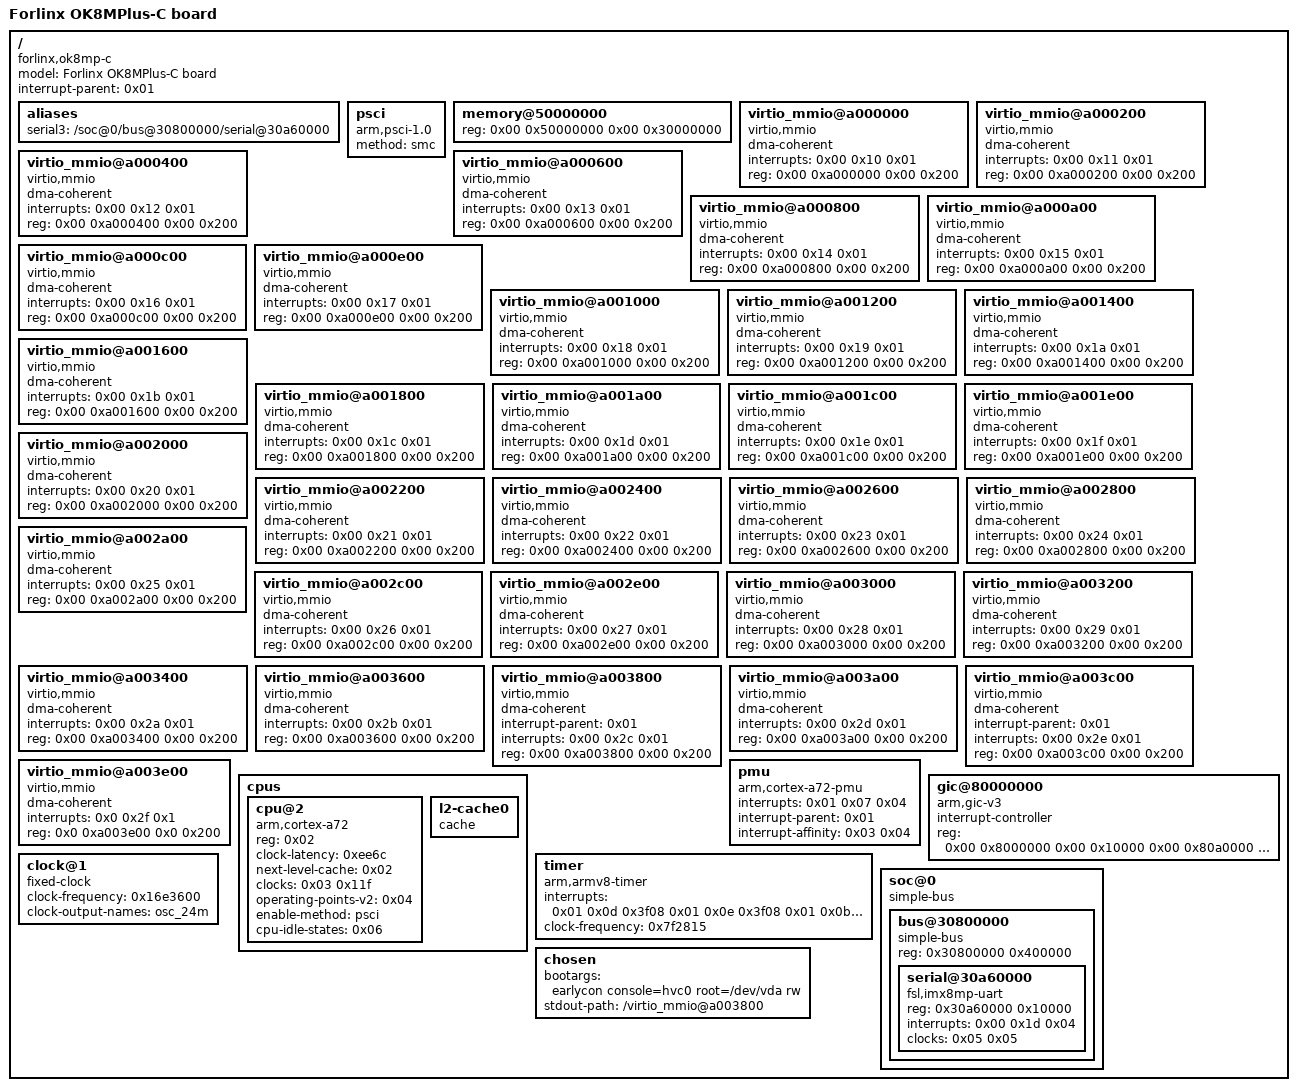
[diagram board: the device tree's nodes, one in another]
/dts-v1/;

/ {
	compatible = "forlinx,ok8mp-c\0fsl,imx8mp-evk\0fsl,imx8mp";
	model = "Forlinx OK8MPlus-C board";
	interrupt-parent = <0x01>;
	#address-cells = <0x02>;
	#size-cells = <0x02>;

	aliases {
		serial3 = "/soc@0/bus@30800000/serial@30a60000";
	};

	psci {
		compatible = "arm,psci-1.0";
		method = "smc";
	};

	memory@50000000 {
		device_type = "memory";
		reg = <0x00 0x50000000 0x00 0x30000000>;
	};

	virtio_mmio@a000000 {
		dma-coherent;
		interrupts = <0x00 0x10 0x01>;
		reg = <0x00 0xa000000 0x00 0x200>;
		compatible = "virtio,mmio";
	};

	virtio_mmio@a000200 {
		dma-coherent;
		interrupts = <0x00 0x11 0x01>;
		reg = <0x00 0xa000200 0x00 0x200>;
		compatible = "virtio,mmio";
	};

	virtio_mmio@a000400 {
		dma-coherent;
		interrupts = <0x00 0x12 0x01>;
		reg = <0x00 0xa000400 0x00 0x200>;
		compatible = "virtio,mmio";
	};

	virtio_mmio@a000600 {
		dma-coherent;
		interrupts = <0x00 0x13 0x01>;
		reg = <0x00 0xa000600 0x00 0x200>;
		compatible = "virtio,mmio";
	};

	virtio_mmio@a000800 {
		dma-coherent;
		interrupts = <0x00 0x14 0x01>;
		reg = <0x00 0xa000800 0x00 0x200>;
		compatible = "virtio,mmio";
	};

	virtio_mmio@a000a00 {
		dma-coherent;
		interrupts = <0x00 0x15 0x01>;
		reg = <0x00 0xa000a00 0x00 0x200>;
		compatible = "virtio,mmio";
	};

	virtio_mmio@a000c00 {
		dma-coherent;
		interrupts = <0x00 0x16 0x01>;
		reg = <0x00 0xa000c00 0x00 0x200>;
		compatible = "virtio,mmio";
	};

	virtio_mmio@a000e00 {
		dma-coherent;
		interrupts = <0x00 0x17 0x01>;
		reg = <0x00 0xa000e00 0x00 0x200>;
		compatible = "virtio,mmio";
	};

	virtio_mmio@a001000 {
		dma-coherent;
		interrupts = <0x00 0x18 0x01>;
		reg = <0x00 0xa001000 0x00 0x200>;
		compatible = "virtio,mmio";
	};

	virtio_mmio@a001200 {
		dma-coherent;
		interrupts = <0x00 0x19 0x01>;
		reg = <0x00 0xa001200 0x00 0x200>;
		compatible = "virtio,mmio";
	};

	virtio_mmio@a001400 {
		dma-coherent;
		interrupts = <0x00 0x1a 0x01>;
		reg = <0x00 0xa001400 0x00 0x200>;
		compatible = "virtio,mmio";
	};

	virtio_mmio@a001600 {
		dma-coherent;
		interrupts = <0x00 0x1b 0x01>;
		reg = <0x00 0xa001600 0x00 0x200>;
		compatible = "virtio,mmio";
	};

	virtio_mmio@a001800 {
		dma-coherent;
		interrupts = <0x00 0x1c 0x01>;
		reg = <0x00 0xa001800 0x00 0x200>;
		compatible = "virtio,mmio";
	};

	virtio_mmio@a001a00 {
		dma-coherent;
		interrupts = <0x00 0x1d 0x01>;
		reg = <0x00 0xa001a00 0x00 0x200>;
		compatible = "virtio,mmio";
	};

	virtio_mmio@a001c00 {
		dma-coherent;
		interrupts = <0x00 0x1e 0x01>;
		reg = <0x00 0xa001c00 0x00 0x200>;
		compatible = "virtio,mmio";
	};

	virtio_mmio@a001e00 {
		dma-coherent;
		interrupts = <0x00 0x1f 0x01>;
		reg = <0x00 0xa001e00 0x00 0x200>;
		compatible = "virtio,mmio";
	};

	virtio_mmio@a002000 {
		dma-coherent;
		interrupts = <0x00 0x20 0x01>;
		reg = <0x00 0xa002000 0x00 0x200>;
		compatible = "virtio,mmio";
	};

	virtio_mmio@a002200 {
		dma-coherent;
		interrupts = <0x00 0x21 0x01>;
		reg = <0x00 0xa002200 0x00 0x200>;
		compatible = "virtio,mmio";
	};

	virtio_mmio@a002400 {
		dma-coherent;
		interrupts = <0x00 0x22 0x01>;
		reg = <0x00 0xa002400 0x00 0x200>;
		compatible = "virtio,mmio";
	};

	virtio_mmio@a002600 {
		dma-coherent;
		interrupts = <0x00 0x23 0x01>;
		reg = <0x00 0xa002600 0x00 0x200>;
		compatible = "virtio,mmio";
	};

	virtio_mmio@a002800 {
		dma-coherent;
		interrupts = <0x00 0x24 0x01>;
		reg = <0x00 0xa002800 0x00 0x200>;
		compatible = "virtio,mmio";
	};

	virtio_mmio@a002a00 {
		dma-coherent;
		interrupts = <0x00 0x25 0x01>;
		reg = <0x00 0xa002a00 0x00 0x200>;
		compatible = "virtio,mmio";
	};

	virtio_mmio@a002c00 {
		dma-coherent;
		interrupts = <0x00 0x26 0x01>;
		reg = <0x00 0xa002c00 0x00 0x200>;
		compatible = "virtio,mmio";
	};

	virtio_mmio@a002e00 {
		dma-coherent;
		interrupts = <0x00 0x27 0x01>;
		reg = <0x00 0xa002e00 0x00 0x200>;
		compatible = "virtio,mmio";
	};

	virtio_mmio@a003000 {
		dma-coherent;
		interrupts = <0x00 0x28 0x01>;
		reg = <0x00 0xa003000 0x00 0x200>;
		compatible = "virtio,mmio";
	};

	virtio_mmio@a003200 {
		dma-coherent;
		interrupts = <0x00 0x29 0x01>;
		reg = <0x00 0xa003200 0x00 0x200>;
		compatible = "virtio,mmio";
	};

	virtio_mmio@a003400 {
		dma-coherent;
		interrupts = <0x00 0x2a 0x01>;
		reg = <0x00 0xa003400 0x00 0x200>;
		compatible = "virtio,mmio";
	};

	virtio_mmio@a003600 {
		dma-coherent;
		interrupts = <0x00 0x2b 0x01>;
		reg = <0x00 0xa003600 0x00 0x200>;
		compatible = "virtio,mmio";
	};

	virtio_mmio@a003800 {
		dma-coherent;
		interrupt-parent = <0x01>;
		interrupts = <0x00 0x2c 0x01>;
		reg = <0x00 0xa003800 0x00 0x200>;
		compatible = "virtio,mmio";
	};

	virtio_mmio@a003a00 {
		dma-coherent;
		interrupts = <0x00 0x2d 0x01>;
		reg = <0x00 0xa003a00 0x00 0x200>;
		compatible = "virtio,mmio";
	};

	virtio_mmio@a003c00 {
		dma-coherent;
		interrupt-parent = <0x01>;
		interrupts = <0x00 0x2e 0x01>;
		reg = <0x00 0xa003c00 0x00 0x200>;
		compatible = "virtio,mmio";
	};

	// virtio disk-first
	virtio_mmio@a003e00 {
	 	dma-coherent;
	 	interrupts = <0x0 0x2f 0x1>;
	 	reg = <0x0 0xa003e00 0x0 0x200>;
	 	compatible = "virtio,mmio";
	};

	cpus {
		#address-cells = <0x01>;
		#size-cells = <0x00>;

		cpu@2 {
			device_type = "cpu";
			compatible = "arm,cortex-a72";
			reg = <0x02>;
			clock-latency = <0xee6c>;
			next-level-cache = <0x02>;
			clocks = <0x03 0x11f>;
			operating-points-v2 = <0x04>;
			enable-method = "psci";
			#cooling-cells = <0x02>;
			cpu-idle-states = <0x06>;
			phandle = <0x13>;
		};

		l2-cache0 {
			compatible = "cache";
			phandle = <0x02>;
		};
	};

	pmu {
		compatible = "arm,cortex-a72-pmu";
		interrupts = <0x01 0x07 0x04>;
		interrupt-parent = <0x01>;
		interrupt-affinity = <0x03 0x04>;
	};

	gic@80000000 {
		compatible = "arm,gic-v3";
		#interrupt-cells = <0x03>;
		interrupt-controller;
		reg = <0x00 0x8000000 0x00 0x10000 0x00 0x80a0000 0x00 0xf60000>;
		phandle = <0x01>;
	};

	timer {
		compatible = "arm,armv8-timer";
		interrupts = <0x01 0x0d 0x3f08 0x01 0x0e 0x3f08 0x01 0x0b 0x3f08 0x01 0x0a 0x3f08>;
		clock-frequency = <0x7f2815>;
	};

	clock@1 {
		compatible = "fixed-clock";
		#clock-cells = <0x00>;
		clock-frequency = <0x16e3600>;
		clock-output-names = "osc_24m";
		phandle = <0x05>;
	};

	soc@0 {
		compatible = "simple-bus";
		#address-cells = <0x01>;
		#size-cells = <0x01>;
		ranges = <0x00 0x00 0x00 0x3e000000>;

		bus@30800000 {
			compatible = "simple-bus";
			#address-cells = <0x01>;
			#size-cells = <0x01>;
			reg = <0x30800000 0x400000>;
			ranges;

			serial@30a60000 {
				compatible = "fsl,imx8mp-uart\0fsl,imx6q-uart";
				reg = <0x30a60000 0x10000>;
				interrupts = <0x00 0x1d 0x04>;
				clocks = <0x05 0x05>;
				clock-names = "ipg\0per";
				status = "okay";
			};
		};
	};

	chosen {
		bootargs = "earlycon console=hvc0 root=/dev/vda rw";
		stdout-path = "/virtio_mmio@a003800";
	};
};
